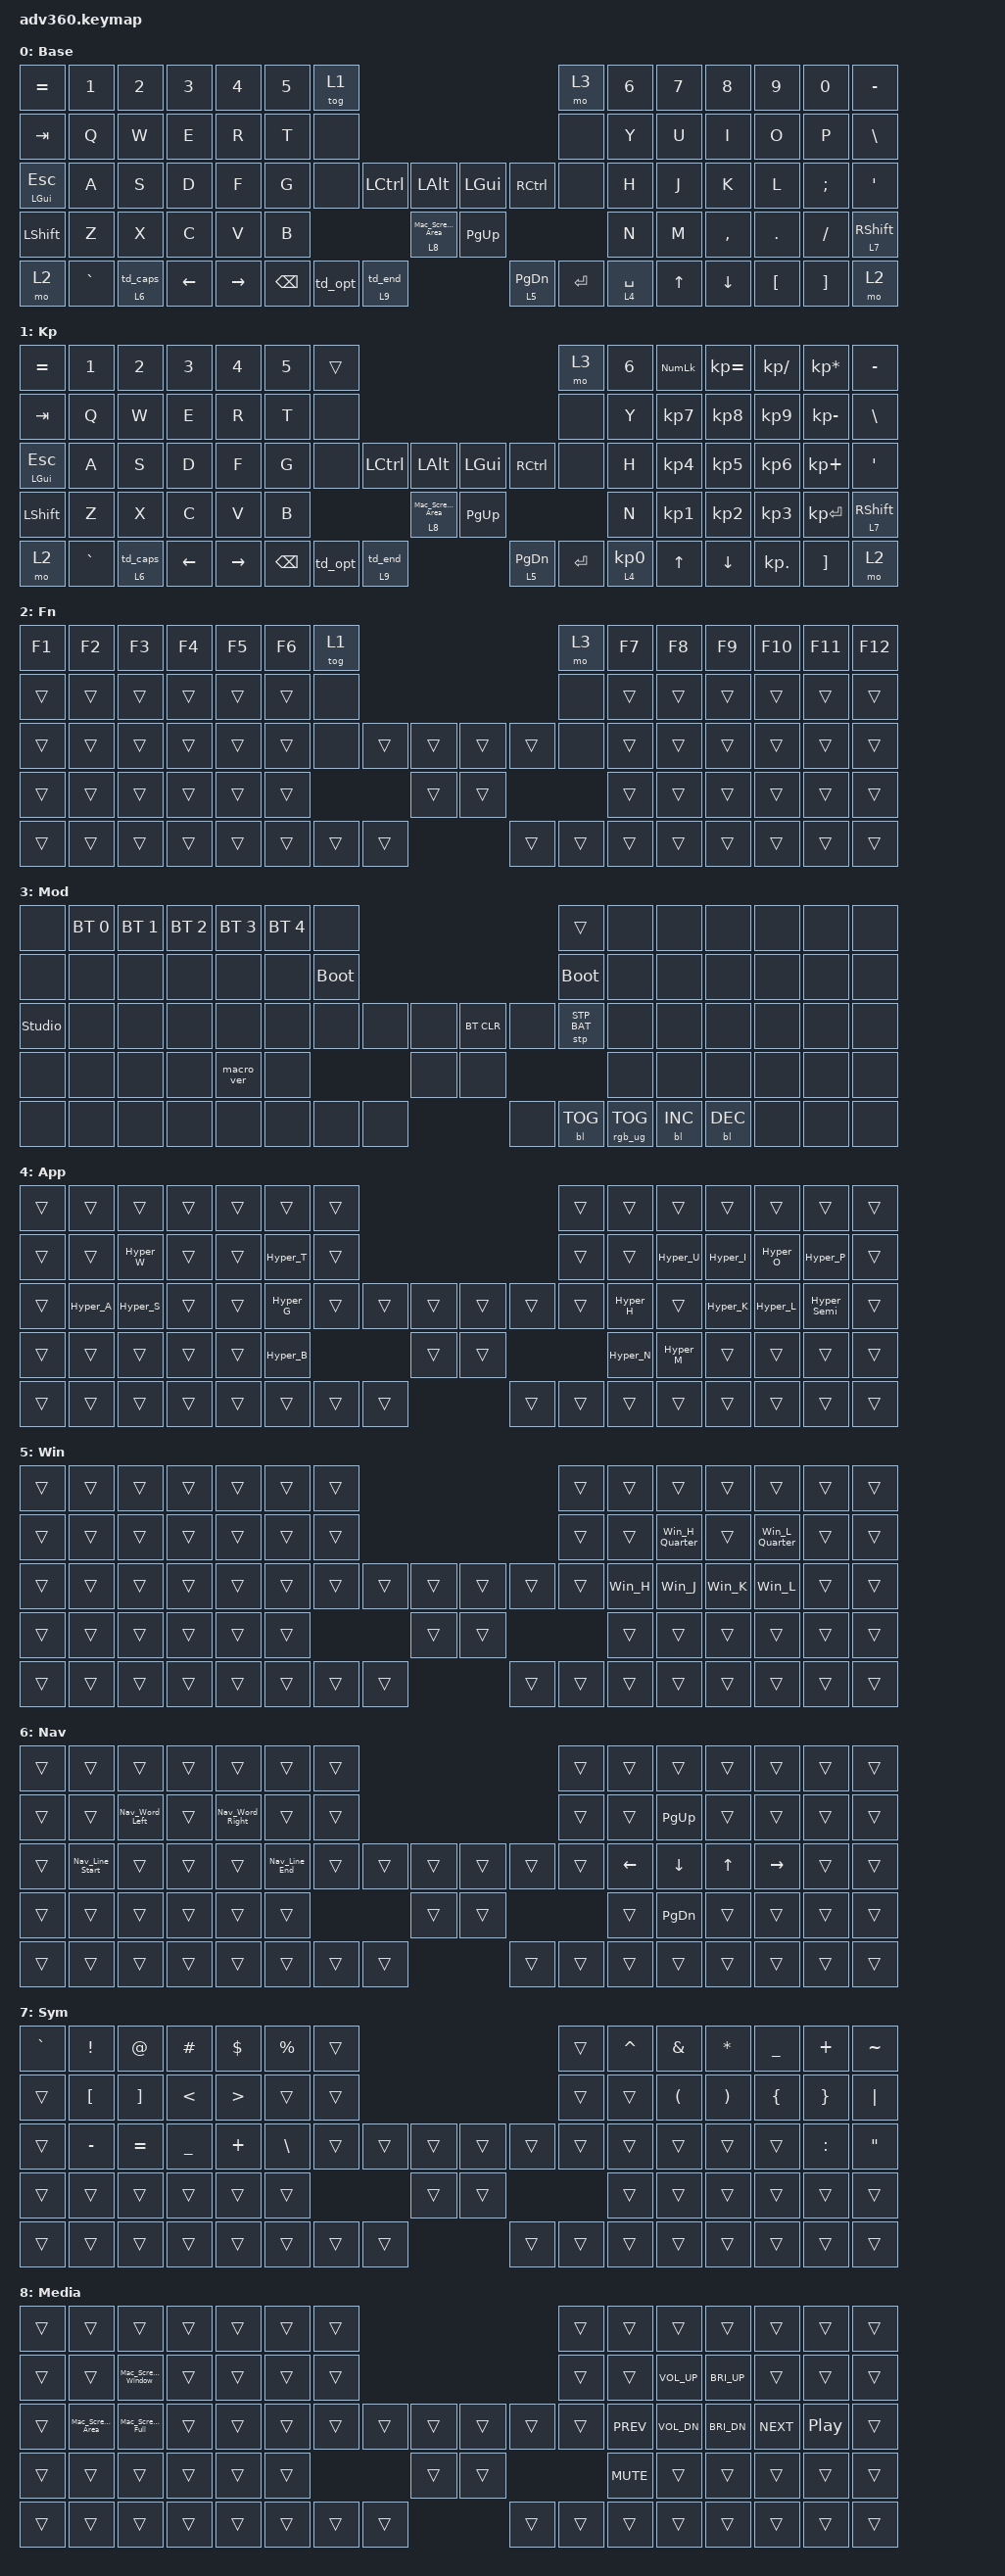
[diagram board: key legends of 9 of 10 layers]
#include <behaviors.dtsi>
#include <dt-bindings/zmk/keys.h>
#include <dt-bindings/zmk/bt.h>
#include <dt-bindings/zmk/rgb.h>
#include <dt-bindings/zmk/stp.h>
#include <dt-bindings/zmk/backlight.h>
#include <dt-bindings/zmk/pointing.h>

/ {
    behaviors {
      #include "macros.dtsi"
      #include "version.dtsi"

      hm: homerow_mods {
          compatible = "zmk,behavior-hold-tap";
          label = "HOMEROW_MODS";
          #binding-cells = <2>;
          tapping-term-ms = <200>;
          quick_tap_ms = <175>;
          flavor = "tap-preferred";
          bindings = <&kp>, <&kp>;
      };

      td_opt: tap_dance_option {
          compatible = "zmk,behavior-tap-dance";
          label = "TAP_DANCE_OPTION";
          #binding-cells = <0>;
          tapping-term-ms = <200>;
          bindings = <&kp LALT>, <&Mac_Opt_Space>;
      };

      ht_enter: holdtap_enter {
          compatible = "zmk,behavior-hold-tap";
          label = "HOLD_TAP_ENTER";
          #binding-cells = <2>;
          tapping-term-ms = <200>;
          quick_tap_ms = <175>;
          flavor = "tap-preferred";
          bindings = <&kp>, <&kp>;
      };

      td_caps: tap_dance_caps {
          compatible = "zmk,behavior-tap-dance";
          label = "TAP_DANCE_CAPS";
          #binding-cells = <0>;
          tapping-term-ms = <200>;
          bindings = <&caps_word>, <&kp CAPS>;
      };

      td_end: tap_dance_end {
          compatible = "zmk,behavior-tap-dance";
          label = "TAP_DANCE_END";
          #binding-cells = <0>;
          tapping-term-ms = <200>;
          bindings = <&kp END>, <&kp LC(SPACE)>;
      };

      lt_spc: layer_tap_space {
          compatible = "zmk,behavior-hold-tap";
          label = "LAYER_TAP_SPACE";
          #binding-cells = <2>;
          tapping-term-ms = <200>;
          quick_tap_ms = <175>;
          flavor = "tap-preferred";
          bindings = <&mo>, <&kp>;
      };

      lt_pgdn: layer_tap_pgdn {
          compatible = "zmk,behavior-hold-tap";
          label = "LAYER_TAP_PGDN";
          #binding-cells = <2>;
          tapping-term-ms = <200>;
          quick_tap_ms = <175>;
          flavor = "tap-preferred";
          bindings = <&mo>, <&kp>;
      };

      lt_caps: layer_tap_caps {
          compatible = "zmk,behavior-hold-tap";
          label = "LAYER_TAP_CAPS";
          #binding-cells = <2>;
          tapping-term-ms = <200>;
          quick_tap_ms = <175>;
          flavor = "tap-preferred";
          bindings = <&mo>, <&td_caps>;
      };

      lt_rshft: layer_tap_rshift {
          compatible = "zmk,behavior-hold-tap";
          label = "LAYER_TAP_RSHIFT";
          #binding-cells = <2>;
          tapping-term-ms = <200>;
          quick_tap_ms = <175>;
          flavor = "tap-preferred";
          bindings = <&mo>, <&kp>;
      };

      lt_home: layer_tap_home {
          compatible = "zmk,behavior-hold-tap";
          label = "LAYER_TAP_HOME";
          #binding-cells = <2>;
          tapping-term-ms = <200>;
          quick_tap_ms = <175>;
          flavor = "tap-preferred";
          bindings = <&mo>, <&Mac_Screenshot_Area>;
      };

      lt_grave: layer_tap_grave {
          compatible = "zmk,behavior-hold-tap";
          label = "LAYER_TAP_GRAVE";
          #binding-cells = <2>;
          tapping-term-ms = <200>;
          quick_tap_ms = <175>;
          flavor = "tap-preferred";
          bindings = <&mo>, <&kp>;
      };

      lt_end: layer_tap_end {
          compatible = "zmk,behavior-hold-tap";
          label = "LAYER_TAP_END";
          #binding-cells = <2>;
          tapping-term-ms = <200>;
          quick_tap_ms = <175>;
          flavor = "tap-preferred";
          bindings = <&mo>, <&td_end>;
      };

      ht_lshft: holdtap_lshift {
          compatible = "zmk,behavior-hold-tap";
          label = "HOLD_TAP_LSHIFT";
          #binding-cells = <2>;
          tapping-term-ms = <200>;
          quick_tap_ms = <175>;
          flavor = "tap-preferred";
          bindings = <&kp>, <&kp>;
      };
    };

  keymap {
    compatible = "zmk,keymap";

    default_layer {
      display-name = "Base";
      bindings = <
        &kp EQUAL &kp N1    &kp N2   &kp N3   &kp N4     &kp N5 &tog 1                                                           &mo 3 &kp N6 &kp N7 &kp N8    &kp N9   &kp N0   &kp MINUS
        &kp TAB   &kp Q     &kp W    &kp E    &kp R      &kp T  &none                                                            &none &kp Y  &kp U  &kp I     &kp O    &kp P    &kp BSLH
        &ht_enter LGUI ESC   &kp A     &kp S    &kp D    &kp F      &kp G  &none           &kp LCTRL &kp LALT &kp LGUI  &kp RCTRL           &none &kp H  &kp J  &kp K     &kp L    &kp SEMI &kp SQT
        &kp LSHFT &kp Z     &kp X    &kp C    &kp V      &kp B                            &lt_home 8 0 &kp PG_UP                      &kp N  &kp M  &kp COMMA &kp DOT  &kp FSLH &lt_rshft 7 RSHFT
        &mo 2     &kp GRAVE &lt_caps 6 0 &kp LEFT &kp RIGHT                &kp BSPC &td_opt   &lt_end 9 0  &lt_pgdn 5 PG_DN &kp ENTER &lt_spc 4 SPACE        &kp UP &kp DOWN  &kp LBKT &kp RBKT &mo 2
      >;
    };
    keypad {
      display-name = "Kp";
      bindings = <
        &kp EQUAL &kp N1    &kp N2   &kp N3   &kp N4     &kp N5 &trans                                                           &mo 3 &kp N6 &kp KP_NUM &kp KP_EQUAL &kp KP_DIVIDE &kp KP_MULTIPLY &kp MINUS
        &kp TAB   &kp Q     &kp W    &kp E    &kp R      &kp T  &none                                                            &none &kp Y  &kp KP_N7  &kp KP_N8    &kp KP_N9     &kp KP_MINUS    &kp BSLH
        &ht_enter LGUI ESC   &kp A     &kp S    &kp D    &kp F      &kp G  &none           &kp LCTRL &kp LALT &kp LGUI  &kp RCTRL           &none &kp H  &kp KP_N4  &kp KP_N5    &kp KP_N6     &kp KP_PLUS     &kp SQT
        &kp LSHFT &kp Z     &kp X    &kp C    &kp V      &kp B                            &lt_home 8 0 &kp PG_UP                      &kp N  &kp KP_N1  &kp KP_N2    &kp KP_N3     &kp KP_ENTER    &lt_rshft 7 RSHFT
        &mo 2     &kp GRAVE &lt_caps 6 0 &kp LEFT &kp RIGHT                &kp BSPC &td_opt   &lt_end 9 0  &lt_pgdn 5 PG_DN &kp ENTER &lt_spc 4 KP_N0        &kp UP     &kp DOWN     &kp KP_DOT    &kp RBKT        &mo 2
      >;
    };
    fn {
      display-name = "Fn";
      bindings = <
        &kp F1 &kp F2 &kp F3 &kp F4 &kp F5 &kp F6 &tog 1                                           &mo 3 &kp F7 &kp F8 &kp F9 &kp F10 &kp F11 &kp F12
        &trans &trans &trans &trans &trans &trans  &none                                           &none &trans &trans &trans &trans  &trans  &trans
        &trans &trans &trans &trans &trans &trans  &none        &trans &trans &trans &trans        &none &trans &trans &trans &trans  &trans  &trans
        &trans &trans &trans &trans &trans &trans                      &trans &trans                     &trans &trans &trans &trans  &trans  &trans
        &trans &trans &trans &trans &trans               &trans &trans &trans &trans &trans &trans              &trans &trans &trans  &trans  &trans
      >;
    };
    mod {
      display-name = "Mod";
      bindings = <
        &none &bt BT_SEL 0 &bt BT_SEL 1 &bt BT_SEL 2 &bt BT_SEL 3 &bt BT_SEL 4 &none                                                                     &trans                 &none        &none        &none        &none &none &none
        &none &none        &none        &none        &none        &none        &bootloader                                                               &bootloader            &none        &none        &none        &none &none &none
        &studio_unlock &none        &none        &none        &none        &none        &none                   &none &none &bt BT_CLR &none                      &stp STP_BAT &none        &none        &none        &none &none &none
        &none &none        &none        &none        &macro_ver   &none                                      &none &none                                                        &none        &none        &none        &none &none &none
        &none &none        &none        &none        &none                                       &none &none &none &none      &bl BL_TOG &rgb_ug RGB_TOG                                     &bl BL_INC   &bl BL_DEC   &none &none &none
      >;
    };
    app {
      display-name = "App";
      bindings = <
        &trans &trans &trans &trans &trans &trans &trans                                                           &trans &trans &trans &trans &trans &trans &trans
        &trans &trans &Hyper_W &trans &trans &Hyper_T &trans                                                       &trans &trans &Hyper_U &Hyper_I &Hyper_O &Hyper_P &trans
        &trans &Hyper_A &Hyper_S &trans &trans &Hyper_G &trans        &trans &trans &trans &trans                  &trans &Hyper_H &trans &Hyper_K &Hyper_L &Hyper_Semi &trans
        &trans &trans &trans &trans &trans &Hyper_B                              &trans &trans                          &Hyper_N &Hyper_M &trans &trans &trans &trans
        &trans &trans &trans &trans &trans                      &trans &trans      &trans &trans &trans &trans                       &trans &trans &trans &trans &trans
      >;
    };

    window {
      display-name = "Win";
      bindings = <
        &trans &trans &trans &trans &trans &trans &trans                                                           &trans &trans &trans &trans &trans &trans &trans
        &trans &trans &trans &trans &trans &trans &trans                                                           &trans &trans &Win_H_Quarter &trans &Win_L_Quarter &trans &trans
        &trans &trans &trans &trans &trans &trans &trans        &trans &trans &trans &trans                        &trans &Win_H &Win_J &Win_K &Win_L &trans &trans
        &trans &trans &trans &trans &trans &trans                              &trans &trans                              &trans &trans &trans &trans &trans &trans
        &trans &trans &trans &trans &trans                      &trans &trans      &trans &trans &trans &trans                       &trans &trans &trans &trans &trans
      >;
    };

    nav {
      display-name = "Nav";
      bindings = <
        &trans &trans &trans &trans &trans &trans &trans                                                           &trans &trans &trans &trans &trans &trans &trans
        &trans &trans &Nav_Word_Left &trans &Nav_Word_Right &trans &trans                                          &trans &trans &kp PG_UP &trans &trans &trans &trans
        &trans &Nav_Line_Start &trans &trans &trans &Nav_Line_End &trans  &trans &trans &trans &trans              &trans &kp LEFT &kp DOWN &kp UP &kp RIGHT &trans &trans
        &trans &trans &trans &trans &trans &trans                              &trans &trans                              &trans &kp PG_DN &trans &trans &trans &trans
        &trans &trans &trans &trans &trans                      &trans &trans      &trans &trans &trans &trans                       &trans &trans &trans &trans &trans
      >;
    };

    symbol {
      display-name = "Sym";
      bindings = <
        &kp GRAVE &kp EXCL &kp AT &kp HASH &kp DLLR &kp PRCNT &trans                                                &trans &kp CARET &kp AMPS &kp STAR &kp UNDER &kp PLUS &kp TILDE
        &trans &kp LBKT &kp RBKT &kp LT &kp GT &trans &trans                                                        &trans &trans &kp LPAR &kp RPAR &kp LBRC &kp RBRC &kp PIPE
        &trans &kp MINUS &kp EQUAL &kp UNDER &kp PLUS &kp BSLH &trans  &trans &trans &trans &trans                  &trans &trans &trans &trans &trans &kp COLON &kp DQT
        &trans &trans &trans &trans &trans &trans                              &trans &trans                              &trans &trans &trans &trans &trans &trans
        &trans &trans &trans &trans &trans                      &trans &trans      &trans &trans &trans &trans                       &trans &trans &trans &trans &trans
      >;
    };

    media {
      display-name = "Media";
      bindings = <
        &trans &trans &trans &trans &trans &trans &trans                                                           &trans &trans &trans &trans &trans &trans &trans
        &trans &trans &Mac_Screenshot_Window &trans &trans &trans &trans                                           &trans &trans &kp C_VOL_UP &kp C_BRI_UP &trans &trans &trans
        &trans &Mac_Screenshot_Area &Mac_Screenshot_Full &trans &trans &trans &trans  &trans &trans &trans &trans  &trans &kp C_PREV &kp C_VOL_DN &kp C_BRI_DN &kp C_NEXT &kp C_PP &trans
        &trans &trans &trans &trans &trans &trans                              &trans &trans                              &kp C_MUTE &trans &trans &trans &trans &trans
        &trans &trans &trans &trans &trans                      &trans &trans      &trans &trans &trans &trans                       &trans &trans &trans &trans &trans
      >;
    };

    edit {
      display-name = "Edit";
      bindings = <
        &trans &trans &trans &trans &trans &trans &trans                                                           &trans &trans &trans &trans &trans &trans &trans
        &trans &trans &trans &trans &Mac_Redo_Combo &trans &trans                                                  &trans &trans &trans &trans &trans &trans &trans
        &trans &Mac_Select_All &Mac_Save_Combo &trans &trans &trans &trans  &trans &trans &trans &trans            &trans &trans &trans &trans &trans &trans &trans
        &trans &Mac_Undo_Combo &Mac_Cut_Combo &Mac_Copy_Combo &Mac_Paste_Combo &Mac_Flycut &trans        &trans &trans                      &trans &trans &trans &trans &trans &trans
        &trans &trans &trans &trans &trans                      &trans &trans      &trans &trans &trans &trans                       &trans &trans &trans &trans &trans
      >;
    };
  };

  combos {
    compatible = "zmk,combos";

    // Editing combos (home row right hand)
    combo_copy {
      timeout-ms = <50>;
      key-positions = <40 41>; // J + K
      bindings = <&Mac_Copy_Combo>;
    };

    combo_paste {
      timeout-ms = <50>;
      key-positions = <41 42>; // K + L
      bindings = <&Mac_Paste_Combo>;
    };

    combo_cut {
      timeout-ms = <50>;
      key-positions = <40 42>; // J + L
      bindings = <&Mac_Cut_Combo>;
    };

    // Editing combos (home row left hand)
    combo_undo {
      timeout-ms = <50>;
      key-positions = <29 30>; // S + D
      bindings = <&Mac_Undo_Combo>;
    };

    combo_redo {
      timeout-ms = <50>;
      key-positions = <30 31>; // D + F
      bindings = <&Mac_Redo_Combo>;
    };

    combo_save {
      timeout-ms = <50>;
      key-positions = <31 32>; // F + G
      bindings = <&Mac_Save_Combo>;
    };

    // Tab management combos (top row)
    combo_new_tab {
      timeout-ms = <50>;
      key-positions = <15 16>; // W + E
      bindings = <&Mac_New_Tab>;
    };

    combo_close_tab {
      timeout-ms = <50>;
      key-positions = <16 17>; // E + R
      bindings = <&Mac_Close_Tab>;
    };

    combo_reopen_tab {
      timeout-ms = <50>;
      key-positions = <14 15>; // Q + W
      bindings = <&Mac_Reopen_Tab>;
    };
  };
};
